# nrf54lilium_network register map
Vendor: Nordic Semiconductor; Series: nrf54; File version: 1
nRFXX reference description for system-on-chip with dual ARM 32-bit Cortex-M33 microcontrollers
CPU: CM33 r0p4, little endian, MPU, no FPU, 3 interrupt priority bits, 30 interrupts
Registers are 32-bit, read-write, reset 0x0 unless marked. A register's access mark holds for its fields unless they carry their own. Offsets are from the block's base; lines under a group give offsets from that group; [hi:lo] are bit positions; {n}, {i} and the like mark numbered series; 'fields as' and 'values as' point back to an identical list; <NAME> marks a mode.

## Memory map
0x41008000 RADIO size 0x1000 — 2.4 GHz radio 2.4 GHz radio
0x4100D000 ECB size 0x1000 — AES ECB Mode Encryption
0x4100E000 AAR size 0x1000 — Accelerated Address Resolver
0x4100E000 CCM size 0x1000 — AES CCM mode encryption
0x41010000 TEMP size 0x1000 — Temperature Sensor
0x4101A000 COMP size 0x1000 — Comparator
0x4101C000 SAADC size 0x1000 — Analog to Digital Converter
0x418C0500 GPIOINTERNAL size 0x1000 — GPIO Static
0x418C0500 P0 size 0x300 — GPIO Port

## Interrupts
13 ECB
14 AAR_CCM (AAR, CCM)
16 TEMP
26 COMP
28 SAADC

## Further device data
MaxInterrupts=129

## ECB — AES ECB Mode Encryption
Base 0x4100D000
0x00 TASKS_CONFIG wo — Fetches AES Key from CONFIGPTR job list into the KEY registers
  [0] TASKS_CONFIG
    1=Trigger task
0x04 TASKS_STARTECB wo — Start ECB block encrypt
  [0] TASKS_STARTECB
    1=Trigger task
0x08 TASKS_STOPECB wo — Abort a possible executing ECB operation
  [0] TASKS_STOPECB
    1=Trigger task
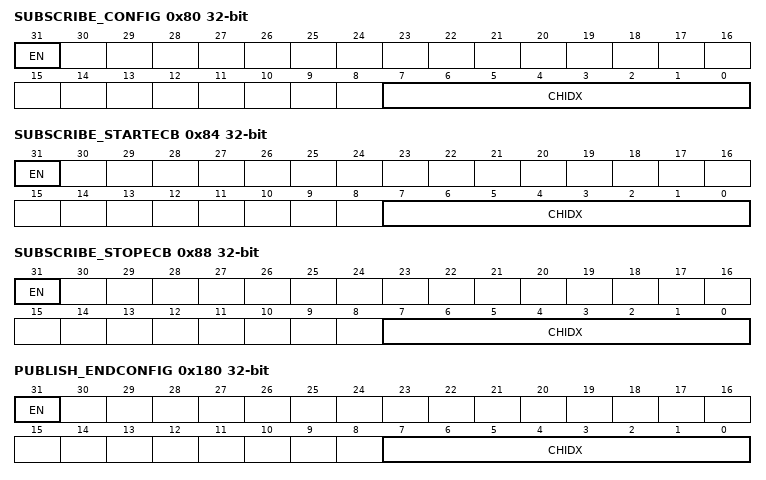
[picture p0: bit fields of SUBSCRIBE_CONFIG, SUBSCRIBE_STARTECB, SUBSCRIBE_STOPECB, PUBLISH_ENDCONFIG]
0x80 SUBSCRIBE_CONFIG — Subscribe configuration for task CONFIG
  [31] EN
    0=Disabled (Disable subscription); 1=Enabled (Enable subscription)
  [7:0] CHIDX — DPPI channel that task CONFIG will subscribe to
0x84 SUBSCRIBE_STARTECB — Subscribe configuration for task STARTECB
  [31] EN
    values as SUBSCRIBE_CONFIG.EN
  [7:0] CHIDX — DPPI channel that task STARTECB will subscribe to
0x88 SUBSCRIBE_STOPECB — Subscribe configuration for task STOPECB
  [31] EN
    values as SUBSCRIBE_CONFIG.EN
  [7:0] CHIDX — DPPI channel that task STOPECB will subscribe to
0x100 EVENTS_ENDCONFIG — ECB block configuration complete
  [0] EVENTS_ENDCONFIG
    0=NotGenerated (Event not generated); 1=Generated (Event generated)
0x104 EVENTS_ENDECB — ECB block encrypt complete
  [0] EVENTS_ENDECB
    values as EVENTS_ENDCONFIG.EVENTS_ENDCONFIG
0x108 EVENTS_ERRORECB — ECB block encrypt aborted because of a STOPECB task or due to an error
  [0] EVENTS_ERRORECB
    values as EVENTS_ENDCONFIG.EVENTS_ENDCONFIG
0x180 PUBLISH_ENDCONFIG — Publish configuration for event ENDCONFIG
  [31] EN
    0=Disabled (Disable publishing); 1=Enabled (Enable publishing)
  [7:0] CHIDX — DPPI channel that event ENDCONFIG will publish to.
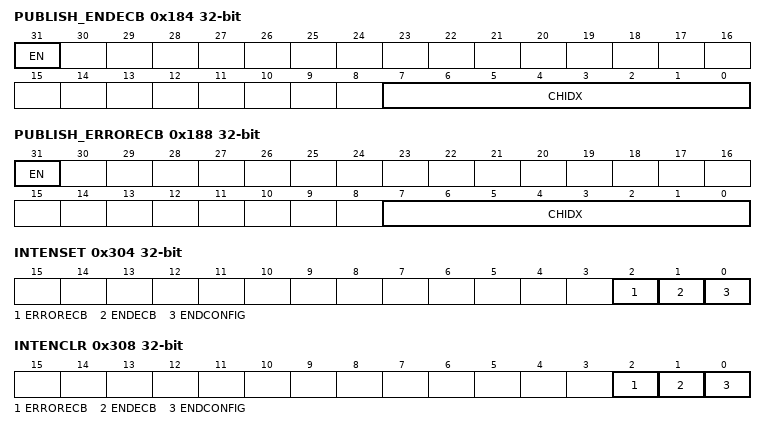
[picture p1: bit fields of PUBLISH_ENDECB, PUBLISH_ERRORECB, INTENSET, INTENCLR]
0x184 PUBLISH_ENDECB — Publish configuration for event ENDECB
  [31] EN
    values as PUBLISH_ENDCONFIG.EN
  [7:0] CHIDX — DPPI channel that event ENDECB will publish to.
0x188 PUBLISH_ERRORECB — Publish configuration for event ERRORECB
  [31] EN
    values as PUBLISH_ENDCONFIG.EN
  [7:0] CHIDX — DPPI channel that event ERRORECB will publish to.
0x304 INTENSET — Enable interrupt
  [all] fields
    on read: 0=Disabled (Read: Disabled); 1=Enabled (Read: Enabled) | on write: 1=Set (Enable)
  [2] ERRORECB — Write '1' to enable interrupt for event ERRORECB
  [1] ENDECB — Write '1' to enable interrupt for event ENDECB
  [0] ENDCONFIG — Write '1' to enable interrupt for event ENDCONFIG
0x308 INTENCLR — Disable interrupt
  [all] fields
    on read: 0=Disabled (Read: Disabled); 1=Enabled (Read: Enabled) | on write: 1=Clear (Disable)
  [2] ERRORECB — Write '1' to disable interrupt for event ERRORECB
  [1] ENDECB — Write '1' to disable interrupt for event ENDECB
  [0] ENDCONFIG — Write '1' to disable interrupt for event ENDCONFIG
0x510 KEY group — Unspecified
  {0x0+4j} VALUE[{j}] (j=0..3) — Description collection: 128-bit AES key
    [31:0] VALUE — AES 128-bit key value, bits (32*(i+1))-1 : (32*i)
0x530 INPTR — ECB input pointer
  [31:0] INPTR — Points to a job list containing unencrypted ECB data structure
0x534 INPTRAMOUNT ro — Number of bytes read from the input data, not including the job list structure
  [31:0] INPTRAMOUNT — Number of bytes read from the input data
0x538 OUTPTR — Output pointer Points to a job list containing encrypted ECB data structure
  [31:0] OUTPTR — Output pointer
0x53C OUTPTRAMOUNT ro — Number of bytes available in the output data, not including the job list structure
  [31:0] OUTPTRAMOUNT — Number of bytes available in the output data

## Licence text in the file
Copyright (c) 2010 - 2020, Nordic Semiconductor ASA All rights reserved. Redistribution and use in source and binary forms, with or without modification, are permitted provided that the following conditions are met: 1. Redistributions of source code must retain the above copyright notice, this list of conditions and the following disclaimer. 2. Redistributions in binary form, except as embedded into a Nordic Semiconductor ASA integrated circuit in a product or a software update for such product, must reproduce the above copyright notice, this list of conditions and the following disclaimer in the documentation and/or other materials provided with the distribution. 3. Neither the name of Nordic Semiconductor ASA nor the names of its contributors may be used to endorse or promote products derived from this software without specific prior written permission. 4. This software, with or without modification, must only be used with a Nordic Semiconductor ASA integrated circuit. 5. Any software provided in binary form under this license must not be reverse engineered, decompiled, modified and/or disassembled. THIS SOFTWARE IS PROVIDED BY NORDIC SEMICONDUCTOR ASA "AS IS" AND ANY EXPRESS OR IMPLIED WARRANTIES, INCLUDING, BUT NOT LIMITED TO, THE IMPLIED WARRANTIES OF MERCHANTABILITY, NONINFRINGEMENT, AND FITNESS FOR A PARTICULAR PURPOSE ARE DISCLAIMED. IN NO EVENT SHALL NORDIC SEMICONDUCTOR ASA OR CONTRIBUTORS BE LIABLE FOR ANY DIRECT, INDIRECT, INCIDENTAL, SPECIAL, EXEMPLARY, OR CONSEQUENTIAL DAMAGES (INCLUDING, BUT NOT LIMITED TO, PROCUREMENT OF SUBSTITUTE GOODS OR SERVICES; LOSS OF USE, DATA, OR PROFITS; OR BUSINESS INTERRUPTION) HOWEVER CAUSED AND ON ANY THEORY OF LIABILITY, WHETHER IN CONTRACT, STRICT LIABILITY, OR TORT (INCLUDING NEGLIGENCE OR OTHERWISE) ARISING IN ANY WAY OUT OF THE USE OF THIS SOFTWARE, EVEN IF ADVISED OF THE POSSIBILITY OF SUCH DAMAGE.
